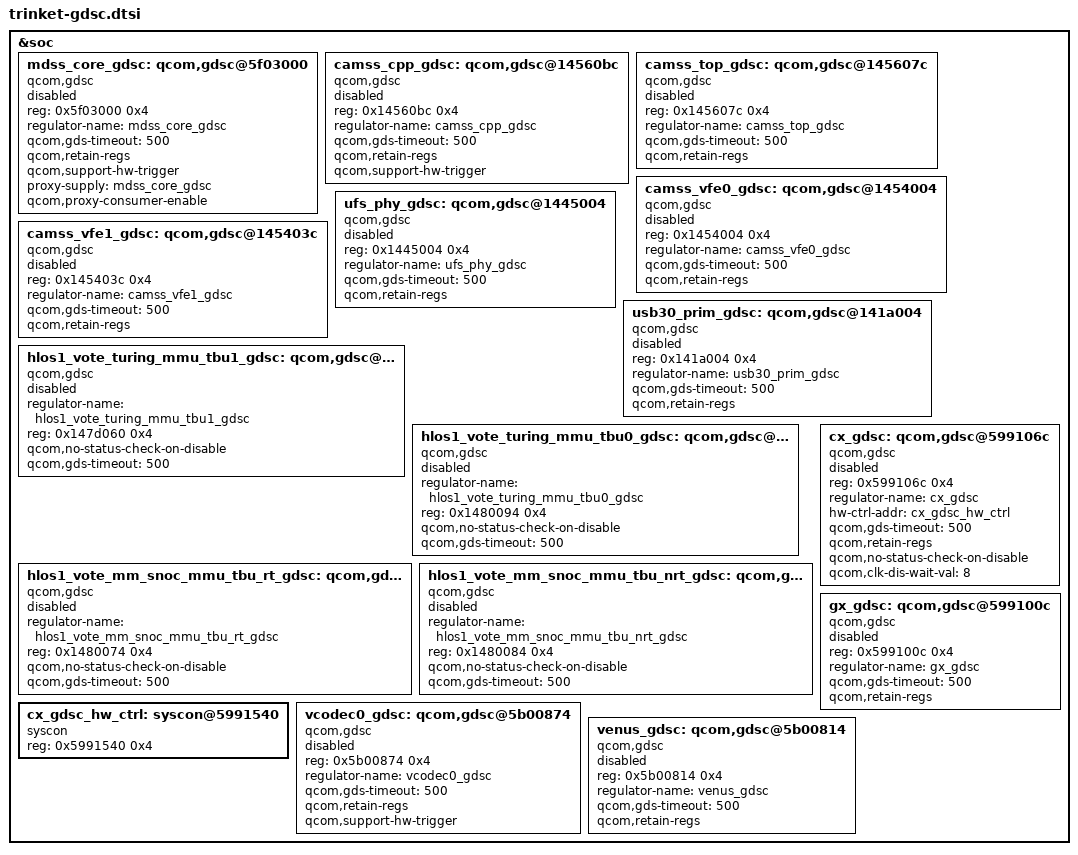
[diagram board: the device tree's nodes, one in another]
&soc {
	/* DISP_CC GDSCs */
	mdss_core_gdsc: qcom,gdsc@5f03000 {
		compatible = "qcom,gdsc";
		reg = <0x5f03000 0x4>;
		regulator-name = "mdss_core_gdsc";
		qcom,gds-timeout = <500>;
		qcom,retain-regs;
		qcom,support-hw-trigger;
		proxy-supply = <&mdss_core_gdsc>;
		qcom,proxy-consumer-enable;
		status = "disabled";
	};

	/* GCC GDSCs */
	camss_cpp_gdsc: qcom,gdsc@14560bc {
		compatible = "qcom,gdsc";
		reg = <0x14560bc 0x4>;
		regulator-name = "camss_cpp_gdsc";
		qcom,gds-timeout = <500>;
		qcom,retain-regs;
		qcom,support-hw-trigger;
		status = "disabled";
	};

	camss_top_gdsc: qcom,gdsc@145607c {
		compatible = "qcom,gdsc";
		reg = <0x145607c 0x4>;
		regulator-name = "camss_top_gdsc";
		qcom,gds-timeout = <500>;
		qcom,retain-regs;
		status = "disabled";
	};

	camss_vfe0_gdsc: qcom,gdsc@1454004 {
		compatible = "qcom,gdsc";
		reg = <0x1454004 0x4>;
		regulator-name = "camss_vfe0_gdsc";
		qcom,gds-timeout = <500>;
		qcom,retain-regs;
		status = "disabled";
	};

	camss_vfe1_gdsc: qcom,gdsc@145403c {
		compatible = "qcom,gdsc";
		reg = <0x145403c 0x4>;
		regulator-name = "camss_vfe1_gdsc";
		qcom,gds-timeout = <500>;
		qcom,retain-regs;
		status = "disabled";
	};

	ufs_phy_gdsc: qcom,gdsc@1445004 {
		compatible = "qcom,gdsc";
		reg = <0x1445004 0x4>;
		regulator-name = "ufs_phy_gdsc";
		qcom,gds-timeout = <500>;
		qcom,retain-regs;
		status = "disabled";
	};

	usb30_prim_gdsc: qcom,gdsc@141a004 {
		compatible = "qcom,gdsc";
		reg = <0x141a004 0x4>;
		regulator-name = "usb30_prim_gdsc";
		qcom,gds-timeout = <500>;
		qcom,retain-regs;
		status = "disabled";
	};

	hlos1_vote_turing_mmu_tbu1_gdsc: qcom,gdsc@147d060 {
		compatible = "qcom,gdsc";
		regulator-name = "hlos1_vote_turing_mmu_tbu1_gdsc";
		reg = <0x147d060 0x4>;
		qcom,no-status-check-on-disable;
		qcom,gds-timeout = <500>;
		status = "disabled";
	};

	hlos1_vote_turing_mmu_tbu0_gdsc: qcom,gdsc@1480094 {
		compatible = "qcom,gdsc";
		regulator-name = "hlos1_vote_turing_mmu_tbu0_gdsc";
		reg = <0x1480094 0x4>;
		qcom,no-status-check-on-disable;
		qcom,gds-timeout = <500>;
		status = "disabled";
	};

	hlos1_vote_mm_snoc_mmu_tbu_rt_gdsc: qcom,gdsc@1480074 {
		compatible = "qcom,gdsc";
		regulator-name = "hlos1_vote_mm_snoc_mmu_tbu_rt_gdsc";
		reg = <0x1480074 0x4>;
		qcom,no-status-check-on-disable;
		qcom,gds-timeout = <500>;
		status = "disabled";
	};

	hlos1_vote_mm_snoc_mmu_tbu_nrt_gdsc: qcom,gdsc@1480084 {
		compatible = "qcom,gdsc";
		regulator-name = "hlos1_vote_mm_snoc_mmu_tbu_nrt_gdsc";
		reg = <0x1480084 0x4>;
		qcom,no-status-check-on-disable;
		qcom,gds-timeout = <500>;
		status = "disabled";
	};

	/* GPU_CC GDSCs */
	cx_gdsc_hw_ctrl: syscon@5991540 {
		compatible = "syscon";
		reg = <0x5991540 0x4>;
	};

	cx_gdsc: qcom,gdsc@599106c {
		compatible = "qcom,gdsc";
		reg = <0x599106c 0x4>;
		regulator-name = "cx_gdsc";
		hw-ctrl-addr = <&cx_gdsc_hw_ctrl>;
		qcom,gds-timeout = <500>;
		qcom,retain-regs;
		qcom,no-status-check-on-disable;
		qcom,clk-dis-wait-val = <8>;
		status = "disabled";
	};

	gx_gdsc: qcom,gdsc@599100c {
		compatible = "qcom,gdsc";
		reg = <0x599100c 0x4>;
		regulator-name = "gx_gdsc";
		qcom,gds-timeout = <500>;
		qcom,retain-regs;
		status = "disabled";
	};

	/* VIDEO_CC GDSCs */
	vcodec0_gdsc: qcom,gdsc@5b00874 {
		compatible = "qcom,gdsc";
		reg = <0x5b00874 0x4>;
		regulator-name = "vcodec0_gdsc";
		qcom,gds-timeout = <500>;
		qcom,retain-regs;
		qcom,support-hw-trigger;
		status = "disabled";
	};

	venus_gdsc: qcom,gdsc@5b00814 {
		compatible = "qcom,gdsc";
		reg = <0x5b00814 0x4>;
		regulator-name = "venus_gdsc";
		qcom,gds-timeout = <500>;
		qcom,retain-regs;
		status = "disabled";
	};
};
